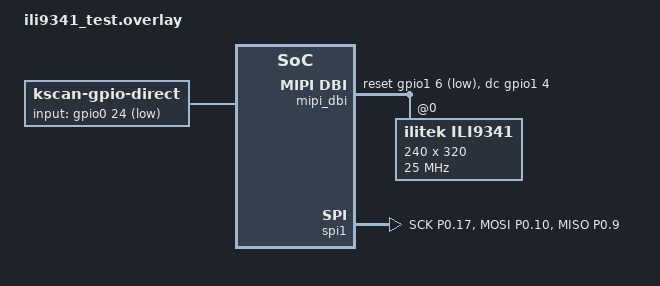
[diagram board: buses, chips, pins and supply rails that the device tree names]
/*
 * ILI9341 2.8" TFT shield for Nice Nano v2 (nRF52840)
 * Uses the Zephyr MIPI DBI SPI interface (required by Zephyr v4.0+).
 *
 * Wiring (Nice Nano v2 label → ILI9341 pin):
 *   3.3 V  → VCC, LED
 *   GND    → GND
 *   D2  (P0.17) → SCK   (SPI clock)
 *   MOSI(P0.10) → SDI
 *   MISO(P0.09) → SDO   (unused with write-only; keep for possible future reads)
 *   D10 (P1.11) → CS    (ILI9341 chip-select, active-low)
 *   D9  (P1.06) → RESET (ILI9341 reset, active-low)
 *   D8  (P1.04) → DC    (data/command: high = data, low = command)
 *   D5  (P0.24) → test button (active-low, pull-up) – optional
 */

#include <dt-bindings/gpio/gpio.h>
#include <dt-bindings/pinctrl/nrf-pinctrl.h>

/* ── chosen & root nodes ─────────────────────────────────────────────────── */
/ {
    chosen {
        zmk,kscan    = &kscan0;
        zephyr,display = &ili9341;
    };

    /* Single test button on D5 (P0.24) – press to generate a keypress */
    kscan0: kscan0 {
        compatible = "zmk,kscan-gpio-direct";
        label = "KSCAN";
        input-gpios = <&gpio0 24 (GPIO_ACTIVE_LOW | GPIO_PULL_UP)>;
    };

    /*
     * MIPI DBI SPI bridge for ILI9341.
     * In Zephyr v4.0+, ili9xxx drivers require a parent MIPI DBI bus node
     * (on-bus: mipi-dbi) instead of being placed directly on the SPI bus.
     * The bridge references &spi1 via spi-dev and reads cs-gpios[0] from it
     * to drive the ILI9341 chip-select.
     */
    mipi_dbi: mipi_dbi {
        compatible = "zephyr,mipi-dbi-spi";
        spi-dev = <&spi1>;
        dc-gpios    = <&gpio1 4 GPIO_ACTIVE_HIGH>;  /* P1.04 – D8 – DC (high=data) */
        reset-gpios = <&gpio1 6 GPIO_ACTIVE_LOW>;   /* P1.06 – D9 – RST             */
        write-only;
        #address-cells = <1>;
        #size-cells = <0>;

        /* ── ILI9341 display ──────────────────────────────────────────── */
        ili9341: ili9341@0 {
            compatible        = "ilitek,ili9341";
            reg               = <0>;
            mipi-max-frequency = <25000000>;   /* 25 MHz */

            /* Portrait 240 × 320 */
            width        = <240>;
            height       = <320>;
            rotation     = <0>;
            pixel-format = <0>;   /* 0 = RGB565 */
        };
    };
};

/* ── pin-control ─────────────────────────────────────────────────────────── */
&pinctrl {
    /* SPIM1 default state */
    spi1_default: spi1_default {
        group1 {
            psels = <NRF_PSEL(SPIM_SCK,  0, 17)>,   /* P0.17 – D2  – SCK  */
                    <NRF_PSEL(SPIM_MOSI, 0, 10)>,   /* P0.10 – MOSI       */
                    <NRF_PSEL(SPIM_MISO, 0,  9)>;   /* P0.09 – MISO       */
        };
    };

    /* SPIM1 sleep state (low-power) */
    spi1_sleep: spi1_sleep {
        group1 {
            psels = <NRF_PSEL(SPIM_SCK,  0, 17)>,
                    <NRF_PSEL(SPIM_MOSI, 0, 10)>,
                    <NRF_PSEL(SPIM_MISO, 0,  9)>;
            low-power-enable;
        };
    };
};

/* ── SPI1 bus ─────────────────────────────────────────────────────────────── */
/*
 * &spi1 has no direct SPI children; the ILI9341 is accessed through the
 * mipi_dbi MIPI DBI SPI bridge above.  cs-gpios[0] is still required so
 * that the MIPI_DBI_SPI_CONFIG_DT macro can resolve the ILI9341 CS GPIO.
 */
&spi1 {
    compatible    = "nordic,nrf-spim";
    status        = "okay";
    pinctrl-0     = <&spi1_default>;
    pinctrl-1     = <&spi1_sleep>;
    pinctrl-names = "default", "sleep";

    cs-gpios = <&gpio1 11 GPIO_ACTIVE_LOW>;   /* P1.11 – D10 – ILI9341 CS */
};
